# CH32V30X register map
Vendor: WCH Ltd.; File version: 1.0
Registers are 32-bit, read-write, reset 0x0 unless marked. A register's access mark holds for its fields unless they carry their own. Offsets are from the block's base; [hi:lo] are bit positions; lines under a group give offsets from that group; {n}, {i} and the like mark numbered series; 'fields as' and 'values as' point back to an identical list.

## EXTI
Base 0x40010400
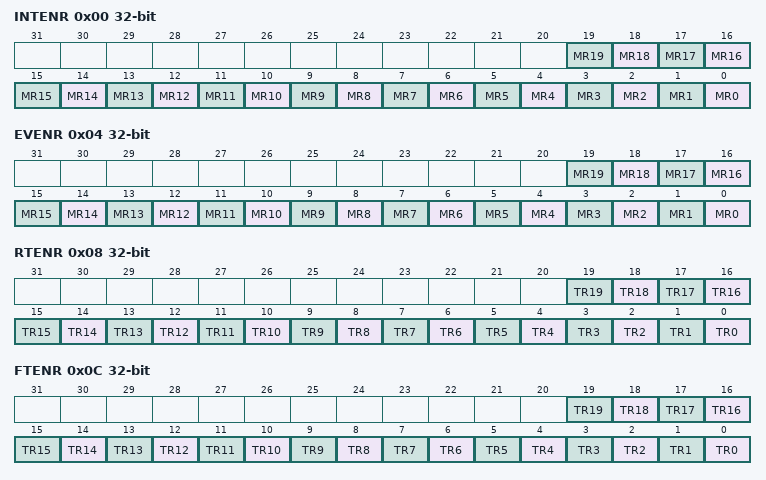
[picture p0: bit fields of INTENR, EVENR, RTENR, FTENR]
0x00 INTENR — Interrupt mask register (EXTI_INTENR)
  [n] MR{n} (n=0..19) — Interrupt Mask on line {n}
0x04 EVENR — Event mask register (EXTI_EVENR)
  [n] MR{n} (n=0..19) — Event Mask on line {n}
0x08 RTENR — Rising Trigger selection register (EXTI_RTENR)
  [n] TR{n} (n=0..19) — Rising trigger event configuration of line {n}
0x0C FTENR — Falling Trigger selection register (EXTI_FTENR)
  [n] TR{n} (n=0..19) — Falling trigger event configuration of line {n}
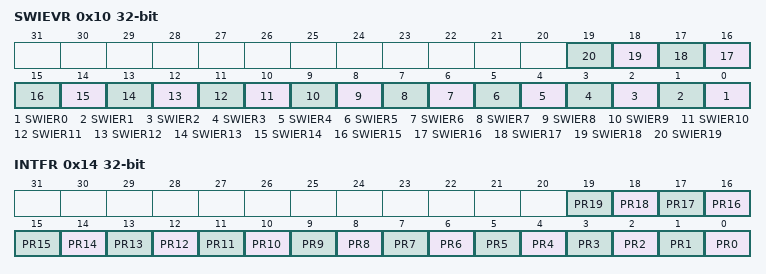
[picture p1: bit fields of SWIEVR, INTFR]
0x10 SWIEVR — Software interrupt event register (EXTI_SWIEVR)
  [n] SWIER{n} (n=0..19) — Software Interrupt on line {n}
0x14 INTFR — Pending register (EXTI_INTFR)
  [n] PR{n} (n=0..19) — Pending bit {n}

## DMA1 — DMA1 controller
Base 0x40020000
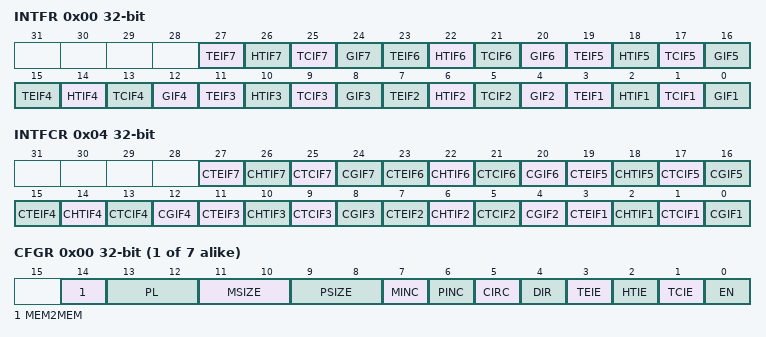
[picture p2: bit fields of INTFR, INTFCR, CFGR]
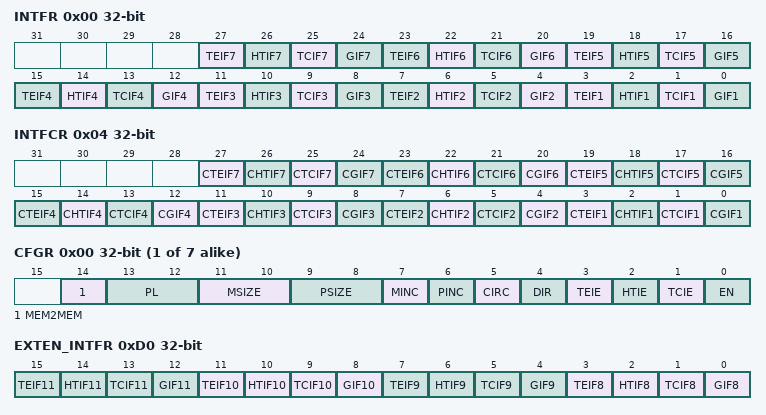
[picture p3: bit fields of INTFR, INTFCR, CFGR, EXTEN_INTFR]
0x00 INTFR ro — DMA interrupt status register (DMA_INTFR)
  [4n-1] TEIF{n} (n=1..7) — Channel {n} Transfer Error flag
  [4n-2] HTIF{n} (n=1..7) — Channel {n} Half Transfer Complete flag
  [4n-3] TCIF{n} (n=1..7) — Channel {n} Transfer Complete flag
  [4n-4] GIF{n} (n=1..7) — Channel {n} Global interrupt flag
0x04 INTFCR wo — DMA interrupt flag clear register (DMA_INTFCR)
  [4n-1] CTEIF{n} (n=1..7) — Channel {n} Transfer Error clear
  [4n-2] CHTIF{n} (n=1..7) — Channel {n} Half Transfer clear
  [4n-3] CTCIF{n} (n=1..7) — Channel {n} Transfer Complete clear
  [4n-4] CGIF{n} (n=1..7) — Channel {n} Global interrupt clear
0x08 CHL{i} (i=1..7; step 0x14) group — Channel cluster: CFGR?, CNTR?, PADDR?, and MADDR? registers
  0x00 CFGR — DMA channel configuration register (DMA_CFGR)
    [14] MEM2MEM — Memory to memory mode
    [13:12] PL — Channel Priority level
    [11:10] MSIZE — Memory size
    [9:8] PSIZE — Peripheral size
    [7] MINC — Memory increment mode
    [6] PINC — Peripheral increment mode
    [5] CIRC — Circular mode
    [4] DIR — Data transfer direction
    [3] TEIE — Transfer error interrupt enable
    [2] HTIE — Half Transfer interrupt enable
    [1] TCIE — Transfer complete interrupt enable
    [0] EN — Channel enable
  0x04 CNTR — DMA channel 1 number of data register
    [15:0] NDT — Number of data to transfer
  0x08 PADDR — DMA channel 1 peripheral address register
    [31:0] PA — Peripheral address
  0x0C MADDR — DMA channel 1 memory address register
    [31:0] MA — Memory address

## DMA2 — DMA2 controller
Base 0x40020400
0x00 INTFR ro — DMA interrupt status register (DMA_INTFR)
  [4n-1] TEIF{n} (n=1..7) — Channel {n} Transfer Error flag
  [4n-2] HTIF{n} (n=1..7) — Channel {n} Half Transfer Complete flag
  [4n-3] TCIF{n} (n=1..7) — Channel {n} Transfer Complete flag
  [4n-4] GIF{n} (n=1..7) — Channel {n} Global interrupt flag
0x04 INTFCR wo — DMA interrupt flag clear register (DMA_INTFCR)
  [4n-1] CTEIF{n} (n=1..7) — Channel {n} Transfer Error clear
  [4n-2] CHTIF{n} (n=1..7) — Channel {n} Half Transfer clear
  [4n-3] CTCIF{n} (n=1..7) — Channel {n} Transfer Complete clear
  [4n-4] CGIF{n} (n=1..7) — Channel {n} Global interrupt clear
0x08 CHL{i} (i=1..7; step 0x14) group — Channel cluster: CFGR?, CNTR?, PADDR?, and MADDR? registers
  0x00 CFGR — DMA channel configuration register (DMA_CFGR)
    [14] MEM2MEM — Memory to memory mode
    [13:12] PL — Channel Priority level
    [11:10] MSIZE — Memory size
    [9:8] PSIZE — Peripheral size
    [7] MINC — Memory increment mode
    [6] PINC — Peripheral increment mode
    [5] CIRC — Circular mode
    [4] DIR — Data transfer direction
    [3] TEIE — Transfer error interrupt enable
    [2] HTIE — Half Transfer interrupt enable
    [1] TCIE — Transfer complete interrupt enable
    [0] EN — Channel enable
  0x04 CNTR — DMA channel 1 number of data register
    [15:0] NDT — Number of data to transfer
  0x08 PADDR — DMA channel 1 peripheral address register
    [31:0] PA — Peripheral address
  0x0C MADDR — DMA channel 1 memory address register
    [31:0] MA — Memory address
{0x10+0x10*i} CHH{i} (i=8..11) group — Channel cluster: CFGR?, CNTR?, PADDR?, and MADDR? registers
  0x00 CFGR — DMA channel configuration register (DMA_CFGR) used in ch32v30x_D8/D8C
    fields as CHL{i}.CFGR
  0x04 CNTR — DMA channel 8 number of data register used in ch32v30x_D8/D8C
    [15:0] NDT — Number of data to transfer
  0x08 PADDR — DMA channel 8 peripheral address register used in ch32v30x_D8/D8C
    [31:0] PA — Peripheral address
  0x0C MADDR — DMA channel 8 memory address register used in ch32v30x_D8/D8C
    [31:0] MA — Memory address
0xD0 EXTEN_INTFR ro — DMA2 EXTEN interrupt status register (DMA_INTFR)used in ch32v30x_D8/D8C
  [4n-29] TEIF{n} (n=8..11) — Channel {n} Transfer Error flag
  [4n-30] HTIF{n} (n=8..11) — Channel {n} Half Transfer Complete flag
  [4n-31] TCIF{n} (n=8..11) — Channel {n} Transfer Complete flag
  [4n-32] GIF{n} (n=8..11) — Channel {n} Global interrupt flag
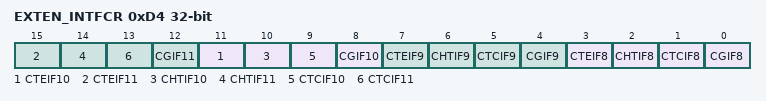
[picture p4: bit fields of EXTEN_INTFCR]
0xD4 EXTEN_INTFCR — DMA2 EXTEN interrupt flag clear register (DMA_INTFCR)used in ch32v30x_D8/D8C
  [4n-29] CTEIF{n} (n=8..11) — Channel {n} Global interrupt clear
  [4n-30] CHTIF{n} (n=8..11) — Channel {n} Global interrupt clear
  [4n-31] CTCIF{n} (n=8..11) — Channel {n} Global interrupt clear
  [4n-32] CGIF{n} (n=8..11) — Channel {n} Global interrupt clear
